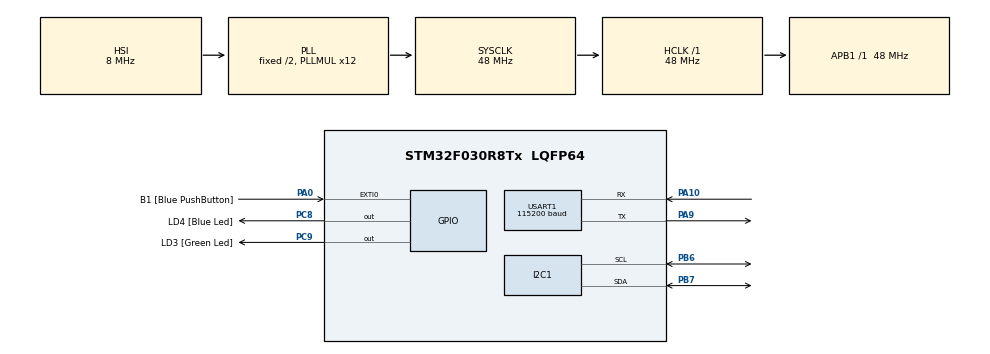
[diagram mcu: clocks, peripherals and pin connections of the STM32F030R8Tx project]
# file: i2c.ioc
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Mcu.Family=STM32F0
Mcu.Name=STM32F030R8Tx
Mcu.Package=LQFP64
NVIC.USART1_IRQn=true\:0\:0\:false\:false\:true\:true\:true
PA0.GPIO_Label=B1 [Blue PushButton]
PA0.GPIO_ModeDefaultEXTI=GPIO_MODE_EVT_RISING
PA0.Signal=GPXTI0
PA10.Mode=Asynchronous
PA10.Signal=USART1_RX
PA13.GPIO_Label=SWDIO
PA13.Signal=SYS_SWDIO
PA14.GPIO_Label=SWCLK
PA14.Signal=SYS_SWCLK
PA9.Mode=Asynchronous
PA9.Signal=USART1_TX
PB6.GPIO_Pu=GPIO_PULLUP
PB6.Mode=I2C
PB6.Signal=I2C1_SCL
PB7.GPIO_Pu=GPIO_PULLUP
PB7.Mode=I2C
PB7.Signal=I2C1_SDA
PC8.GPIO_Label=LD4 [Blue Led]
PC8.Signal=GPIO_Output
PC9.GPIO_Label=LD3 [Green Led]
PC9.Signal=GPIO_Output
ProjectManager.HeapSize=0x200
ProjectManager.StackSize=0x400
ProjectManager.TargetToolchain=STM32CubeIDE
RCC.AHBFreq_Value=48000000
RCC.APB1Freq_Value=48000000
RCC.APB1TimFreq_Value=48000000
RCC.HCLKFreq_Value=48000000
RCC.PLLMUL=RCC_PLL_MUL12
RCC.SYSCLKFreq_VALUE=48000000
RCC.SYSCLKSource=RCC_SYSCLKSOURCE_PLLCLK
USART1.BaudRate=115200
USART1.VirtualMode-Asynchronous=VM_ASYNC
board=32F0308DISCOVERY

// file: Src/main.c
/* USER CODE BEGIN Header */
/**
  ******************************************************************************
  * @file           : main.c
  * @brief          : Main program body
  ******************************************************************************
  * @attention
  *
  * <h2><center>&copy; Copyright (c) 2019 STMicroelectronics.
  * All rights reserved.</center></h2>
  *
  * This software component is licensed by ST under BSD 3-Clause license,
  * the "License"; You may not use this file except in compliance with the
  * License. You may obtain a copy of the License at:
  *                        opensource.org/licenses/BSD-3-Clause
  *
  ******************************************************************************
  */
/* USER CODE END Header */
#include "main.h"

/* USER CODE BEGIN Includes */
#include <stdio.h>
#include "cuart.h"
#include "cgpio.h"
/* USER CODE END Includes */

I2C_HandleTypeDef hi2c1;

UART_HandleTypeDef huart1;

void SystemClock_Config(void);
static void MX_GPIO_Init(void);
static void MX_I2C1_Init(void);
static void MX_USART1_UART_Init(void);

int main(void)
{

  /* MCU Configuration--------------------------------------------------------*/

  /* Reset of all peripherals, Initializes the Flash interface and the Systick. */
  HAL_Init();

  /* USER CODE BEGIN Init */
	setvbuf(stdout, NULL, _IONBF, 0);
  /* USER CODE END Init */

  /* Configure the system clock */
  SystemClock_Config();

  /* Initialize all configured peripherals */
  MX_GPIO_Init();
  MX_I2C1_Init();
  MX_USART1_UART_Init();
  /* USER CODE BEGIN 2 */
	dbg_setup();
	printf(" Program start! %s %s\r\n",__DATE__,__TIME__ );

	oled_init();
	i2c_test();

  /* USER CODE END 2 */

  /* Infinite loop */
  while (1)
  {

    /* USER CODE BEGIN 3 */
	blink_led ();
	dbg_command_scan();

  }
  /* USER CODE END 3 */
}

void SystemClock_Config(void)
{
  RCC_OscInitTypeDef RCC_OscInitStruct = {0};
  RCC_ClkInitTypeDef RCC_ClkInitStruct = {0};
  RCC_PeriphCLKInitTypeDef PeriphClkInit = {0};

  /** Initializes the RCC Oscillators according to the specified parameters
  * in the RCC_OscInitTypeDef structure.
  */
  RCC_OscInitStruct.OscillatorType = RCC_OSCILLATORTYPE_HSI;
  RCC_OscInitStruct.HSIState = RCC_HSI_ON;
  RCC_OscInitStruct.HSICalibrationValue = RCC_HSICALIBRATION_DEFAULT;
  RCC_OscInitStruct.PLL.PLLState = RCC_PLL_ON;
  RCC_OscInitStruct.PLL.PLLSource = RCC_PLLSOURCE_HSI;
  RCC_OscInitStruct.PLL.PLLMUL = RCC_PLL_MUL12;
  RCC_OscInitStruct.PLL.PREDIV = RCC_PREDIV_DIV1;
  if (HAL_RCC_OscConfig(&RCC_OscInitStruct) != HAL_OK)
  {
    Error_Handler();
  }
  /** Initializes the CPU, AHB and APB buses clocks
  */
  RCC_ClkInitStruct.ClockType = RCC_CLOCKTYPE_HCLK|RCC_CLOCKTYPE_SYSCLK
                              |RCC_CLOCKTYPE_PCLK1;
  RCC_ClkInitStruct.SYSCLKSource = RCC_SYSCLKSOURCE_PLLCLK;
  RCC_ClkInitStruct.AHBCLKDivider = RCC_SYSCLK_DIV1;
  RCC_ClkInitStruct.APB1CLKDivider = RCC_HCLK_DIV1;

  if (HAL_RCC_ClockConfig(&RCC_ClkInitStruct, FLASH_LATENCY_1) != HAL_OK)
  {
    Error_Handler();
  }
  PeriphClkInit.PeriphClockSelection = RCC_PERIPHCLK_USART1|RCC_PERIPHCLK_I2C1;
  PeriphClkInit.Usart1ClockSelection = RCC_USART1CLKSOURCE_PCLK1;
  PeriphClkInit.I2c1ClockSelection = RCC_I2C1CLKSOURCE_HSI;
  if (HAL_RCCEx_PeriphCLKConfig(&PeriphClkInit) != HAL_OK)
  {
    Error_Handler();
  }
}

static void MX_I2C1_Init(void)
{

  hi2c1.Instance = I2C1;
  hi2c1.Init.Timing = 0x2000090E;
  hi2c1.Init.OwnAddress1 = 0;
  hi2c1.Init.AddressingMode = I2C_ADDRESSINGMODE_7BIT;
  hi2c1.Init.DualAddressMode = I2C_DUALADDRESS_DISABLE;
  hi2c1.Init.OwnAddress2 = 0;
  hi2c1.Init.OwnAddress2Masks = I2C_OA2_NOMASK;
  hi2c1.Init.GeneralCallMode = I2C_GENERALCALL_DISABLE;
  hi2c1.Init.NoStretchMode = I2C_NOSTRETCH_DISABLE;
  if (HAL_I2C_Init(&hi2c1) != HAL_OK)
  {
    Error_Handler();
  }
  /** Configure Analogue filter
  */
  if (HAL_I2CEx_ConfigAnalogFilter(&hi2c1, I2C_ANALOGFILTER_ENABLE) != HAL_OK)
  {
    Error_Handler();
  }
  /** Configure Digital filter
  */
  if (HAL_I2CEx_ConfigDigitalFilter(&hi2c1, 0) != HAL_OK)
  {
    Error_Handler();
  }

}

static void MX_USART1_UART_Init(void)
{

  huart1.Instance = USART1;
  huart1.Init.BaudRate = 115200;
  huart1.Init.WordLength = UART_WORDLENGTH_8B;
  huart1.Init.StopBits = UART_STOPBITS_1;
  huart1.Init.Parity = UART_PARITY_NONE;
  huart1.Init.Mode = UART_MODE_TX_RX;
  huart1.Init.HwFlowCtl = UART_HWCONTROL_NONE;
  huart1.Init.OverSampling = UART_OVERSAMPLING_16;
  huart1.Init.OneBitSampling = UART_ONE_BIT_SAMPLE_DISABLE;
  huart1.AdvancedInit.AdvFeatureInit = UART_ADVFEATURE_NO_INIT;
  if (HAL_UART_Init(&huart1) != HAL_OK)
  {
    Error_Handler();
  }

}

static void MX_GPIO_Init(void)
{
  GPIO_InitTypeDef GPIO_InitStruct = {0};

  /* GPIO Ports Clock Enable */
  __HAL_RCC_GPIOA_CLK_ENABLE();
  __HAL_RCC_GPIOC_CLK_ENABLE();
  __HAL_RCC_GPIOB_CLK_ENABLE();

  /*Configure GPIO pin Output Level */
  HAL_GPIO_WritePin(GPIOC, LD4_Pin|LD3_Pin, GPIO_PIN_RESET);

  /*Configure GPIO pin : B1_Pin */
  GPIO_InitStruct.Pin = B1_Pin;
  GPIO_InitStruct.Mode = GPIO_MODE_EVT_RISING;
  GPIO_InitStruct.Pull = GPIO_NOPULL;
  HAL_GPIO_Init(B1_GPIO_Port, &GPIO_InitStruct);

  /*Configure GPIO pins : LD4_Pin LD3_Pin */
  GPIO_InitStruct.Pin = LD4_Pin|LD3_Pin;
  GPIO_InitStruct.Mode = GPIO_MODE_OUTPUT_PP;
  GPIO_InitStruct.Pull = GPIO_NOPULL;
  GPIO_InitStruct.Speed = GPIO_SPEED_FREQ_LOW;
  HAL_GPIO_Init(GPIOC, &GPIO_InitStruct);

}

void Error_Handler(void)
{
}

/************************ (C) COPYRIGHT STMicroelectronics *****END OF FILE****/
